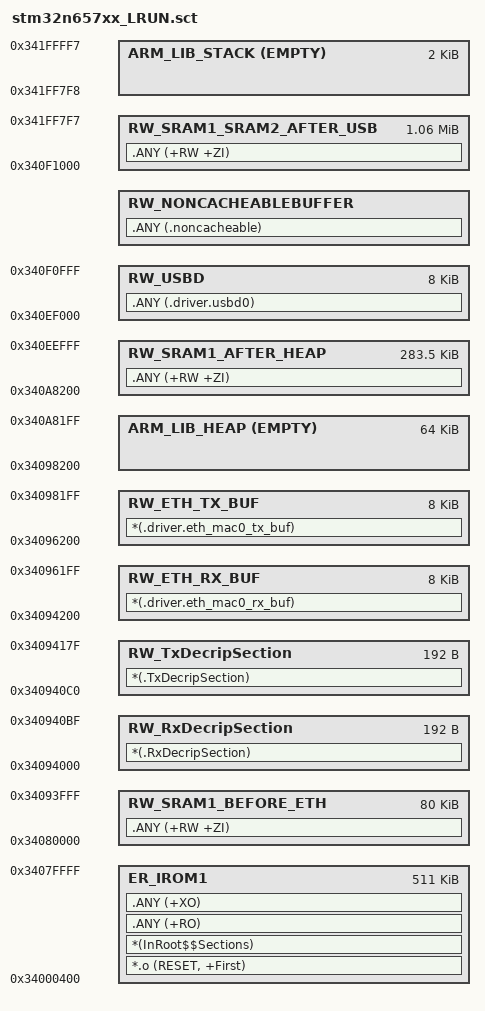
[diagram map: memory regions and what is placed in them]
#! armclang -E --target=arm-arm-none-eabi -mcpu=cortex-m55 -xc


/*--------------------- ROM Configuration ----------------------------------
; <h> ROM Configuration
;   <o0> ROM Base Address <0x0-0xFFFFFFFF:8>
;   <o1> ROM Size (in Bytes) <0x0-0xFFFFFFFF:8>
; </h>
 *----------------------------------------------------------------------------*/
#define __ROM_BASE      0x34000400
#define __ROM_SIZE      0x0007FC00

/*--------------------- Embedded RAM Configuration ---------------------------
; <h> RAM Configuration
;   <o0> RAM Base Address    <0x0-0xFFFFFFFF:8>
;   <o1> RAM Size (in Bytes) <0x0-0xFFFFFFFF:8>
; </h>
 *----------------------------------------------------------------------------*/
#define __RAM_BASE      0x34080000
#define __RAM_SIZE      0x00180000

/*--------------------- Stack / Heap Configuration ---------------------------
; <h> Stack / Heap Configuration
;   <o0> Stack Size (in Bytes) <0x0-0xFFFFFFFF:8>
;   <o1> Heap Size (in Bytes) <0x0-0xFFFFFFFF:8>
; </h>
 *----------------------------------------------------------------------------*/
#define __STACK_SIZE    0x00000800
#define __HEAP_SIZE     0x00010000

/*
// <h> NOINIT Data Configuration
//   <i> specify the size of the section which holds the uninitialized data
//   <o0>  NOINIT Size (in Bytes) <0x0-0xFFFFFFFF:32>
// </h>
 */
#define __NOINIT_SIZE        0x00000000

/*
// <h> CMSE Veneer Configuration
//   <o0>  CMSE Veneer Size (in Bytes) <0x0-0xFFFFFFFF:32>
// </h>
 */
#define __CMSEVENEER_SIZE    0x00002000

/*
// <<< end of configuration section >>>
 */

#define __STACKSEAL_SIZE   ( 8 )

/*----------------------------------------------------------------------------
  User Stack & Heap boundary definition
 *----------------------------------------------------------------------------*/
#define __RAM_END        ( __RAM_BASE + __RAM_SIZE )
#define __ETH_DMA_BASE   0x34094000
#define __ETH_DMA_END    0x34098200
#define __HEAP_BASE      __ETH_DMA_END
#define __HEAP_END       ( __HEAP_BASE + __HEAP_SIZE )
#define __USBD_BASE      0x340EF000
#define __USBD_SIZE      0x00002000
#define __USBD_END       ( __USBD_BASE + __USBD_SIZE )
#define __STACK_TOP      ( __RAM_END - __STACKSEAL_SIZE )  /* starts at end of SRAM2 - 8 byte stack seal */
#define __STACK_BASE     ( __STACK_TOP - __STACK_SIZE )



/*----------------------------------------------------------------------------
  Scatter File Definitions definition
 *----------------------------------------------------------------------------*/
#define __RO_BASE       __ROM_BASE
#define __RO_SIZE       __ROM_SIZE

#define __CV_BASE          ( __ROM_BASE + __ROM_SIZE - __CMSEVENEER_SIZE )
#define __CV_SIZE          ( __CMSEVENEER_SIZE )

#define __LR_BASE          ( __ROM_BASE )
#define __LR_SIZE          ( __ROM_SIZE - __CV_SIZE )

#define __RW1_BASE      __RAM_BASE
#define __RW1_SIZE      ( __ETH_DMA_BASE - __RW1_BASE )
#define __RW2_BASE      __HEAP_END
#define __RW2_SIZE      ( __USBD_BASE - __RW2_BASE )
#define __RW3_BASE      __USBD_END
#define __RW3_SIZE      ( __STACK_BASE - __RW3_BASE )

#define __ER_BASE       __RW1_BASE + __RW1_SIZE
#define __ER_SIZE       0x10000





LR_IROM1 0x34000400 0x0007FC00  {    ; load region size_region
  ER_IROM1 0x34000400 0x0007FC00  {  ; load address = execution address
   *.o (RESET, +First)
   *(InRoot$$Sections)
   .ANY (+RO)
   .ANY (+XO)
  }

  RW_SRAM1_BEFORE_ETH __RW1_BASE __RW1_SIZE  {  ; RW data after LRUN code, before fixed Ethernet DMA buffers
   .ANY (+RW +ZI)
  }

  RW_RxDecripSection 0x34094000 0xC0  {
   *(.RxDecripSection)
  }

  RW_TxDecripSection 0x340940C0 0xC0  {
   *(.TxDecripSection)
  }

  RW_ETH_RX_BUF  0x34094200 0x00002000 {
    *(.driver.eth_mac0_rx_buf)
  }

  RW_ETH_TX_BUF  0x34096200 0x00002000 {
    *(.driver.eth_mac0_tx_buf)
  }

#if __HEAP_SIZE > 0
  ARM_LIB_HEAP  __HEAP_BASE EMPTY  __HEAP_SIZE  {   ; Heap after Ethernet DMA buffers
  }
#endif

  RW_SRAM1_AFTER_HEAP __RW2_BASE __RW2_SIZE  {  ; RW data after heap, before USB/non-cacheable window
   .ANY (+RW +ZI)
  }

  RW_USBD __USBD_BASE __USBD_SIZE  {  ; USB DMA descriptors (fixed hardware address)
   .ANY (.driver.usbd0)
  }

  RW_NONCACHEABLEBUFFER +0 ALIGN 0x4 {  ; RW non-cacheable data inside USB/non-cacheable MPU window when present
   .ANY (.noncacheable)
  }

  RW_SRAM1_SRAM2_AFTER_USB __RW3_BASE __RW3_SIZE  {  ; RW data after USB/non-cacheable window through SRAM2
   .ANY (+RW +ZI)
  }

  ARM_LIB_STACK __STACK_TOP EMPTY -__STACK_SIZE {   ; Reserve empty region for stack
  }
}
